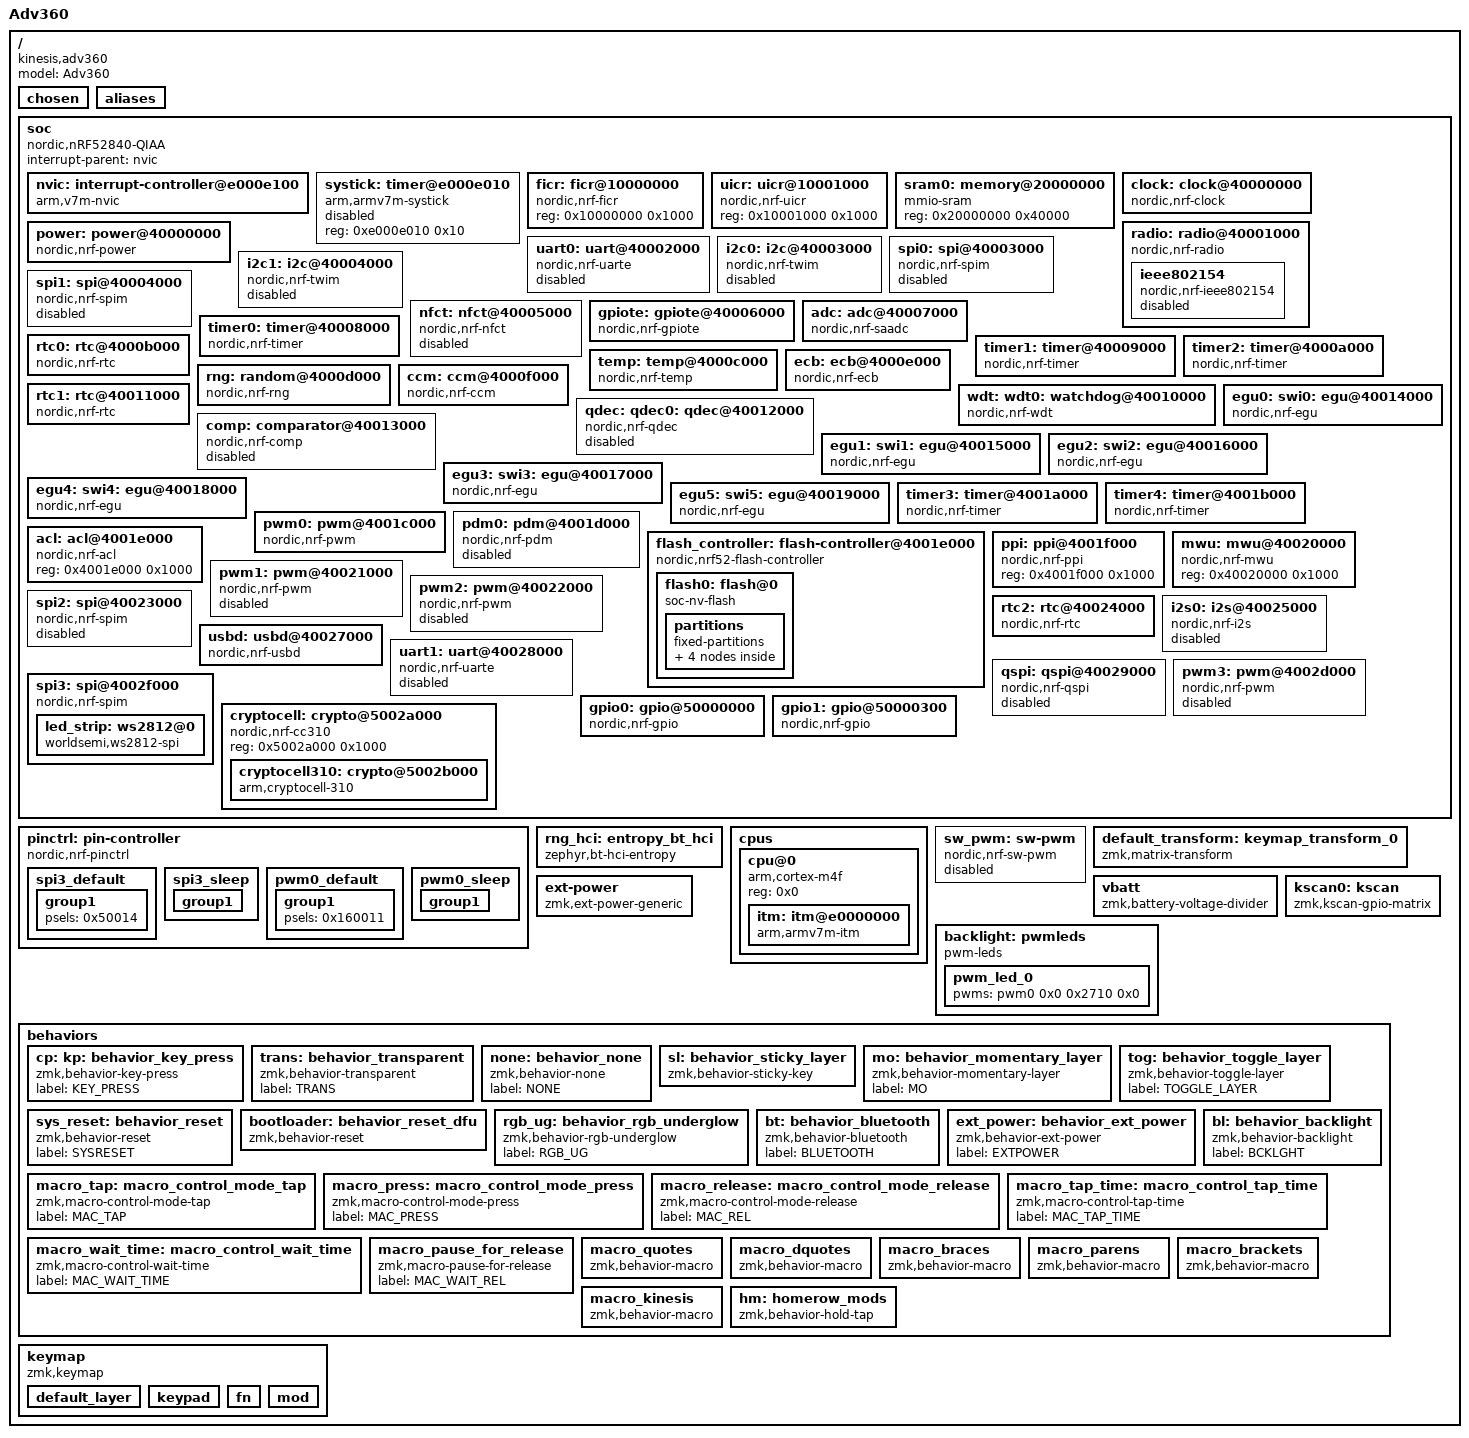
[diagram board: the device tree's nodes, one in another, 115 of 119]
/dts-v1/;

/ {
	#address-cells = < 0x1 >;
	#size-cells = < 0x1 >;
	model = "Adv360";
	compatible = "kinesis,adv360";
	chosen {
		zephyr,entropy = &rng;
		zephyr,flash-controller = &flash_controller;
		zephyr,code-partition = &code_partition;
		zephyr,sram = &sram0;
		zephyr,flash = &flash0;
		zmk,kscan = &kscan0;
		zmk,backlight = &backlight;
		zmk,battery = &vbatt;
		zmk,matrix_transform = &default_transform;
		zmk,underglow = &led_strip;
	};
	aliases {
	};
	soc {
		#address-cells = < 0x1 >;
		#size-cells = < 0x1 >;
		compatible = "nordic,nRF52840-QIAA", "nordic,nRF52840", "nordic,nRF52", "simple-bus";
		interrupt-parent = < &nvic >;
		ranges;
		nvic: interrupt-controller@e000e100 {
			#address-cells = < 0x1 >;
			compatible = "arm,v7m-nvic";
			reg = < 0xe000e100 0xc00 >;
			interrupt-controller;
			#interrupt-cells = < 0x2 >;
			arm,num-irq-priority-bits = < 0x3 >;
			phandle = < 0x1 >;
		};
		systick: timer@e000e010 {
			compatible = "arm,armv7m-systick";
			reg = < 0xe000e010 0x10 >;
			status = "disabled";
		};
		ficr: ficr@10000000 {
			compatible = "nordic,nrf-ficr";
			reg = < 0x10000000 0x1000 >;
			status = "okay";
		};
		uicr: uicr@10001000 {
			compatible = "nordic,nrf-uicr";
			reg = < 0x10001000 0x1000 >;
			status = "okay";
		};
		sram0: memory@20000000 {
			compatible = "mmio-sram";
			reg = < 0x20000000 0x40000 >;
		};
		clock: clock@40000000 {
			compatible = "nordic,nrf-clock";
			reg = < 0x40000000 0x1000 >;
			interrupts = < 0x0 0x1 >;
			status = "okay";
		};
		power: power@40000000 {
			compatible = "nordic,nrf-power";
			reg = < 0x40000000 0x1000 >;
			interrupts = < 0x0 0x1 >;
			status = "okay";
		};
		radio: radio@40001000 {
			compatible = "nordic,nrf-radio";
			reg = < 0x40001000 0x1000 >;
			interrupts = < 0x1 0x1 >;
			status = "okay";
			ieee802154-supported;
			ble-2mbps-supported;
			ble-coded-phy-supported;
			tx-high-power-supported;
			ieee802154: ieee802154 {
				compatible = "nordic,nrf-ieee802154";
				status = "disabled";
			};
		};
		uart0: uart@40002000 {
			compatible = "nordic,nrf-uarte";
			reg = < 0x40002000 0x1000 >;
			interrupts = < 0x2 0x1 >;
			status = "disabled";
		};
		i2c0: i2c@40003000 {
			compatible = "nordic,nrf-twim";
			#address-cells = < 0x1 >;
			#size-cells = < 0x0 >;
			reg = < 0x40003000 0x1000 >;
			clock-frequency = < 0x186a0 >;
			interrupts = < 0x3 0x1 >;
			status = "disabled";
		};
		spi0: spi@40003000 {
			compatible = "nordic,nrf-spim";
			#address-cells = < 0x1 >;
			#size-cells = < 0x0 >;
			reg = < 0x40003000 0x1000 >;
			interrupts = < 0x3 0x1 >;
			max-frequency = < 0x7a1200 >;
			status = "disabled";
		};
		i2c1: i2c@40004000 {
			compatible = "nordic,nrf-twim";
			#address-cells = < 0x1 >;
			#size-cells = < 0x0 >;
			reg = < 0x40004000 0x1000 >;
			clock-frequency = < 0x186a0 >;
			interrupts = < 0x4 0x1 >;
			status = "disabled";
		};
		spi1: spi@40004000 {
			compatible = "nordic,nrf-spim";
			#address-cells = < 0x1 >;
			#size-cells = < 0x0 >;
			reg = < 0x40004000 0x1000 >;
			interrupts = < 0x4 0x1 >;
			max-frequency = < 0x7a1200 >;
			status = "disabled";
		};
		nfct: nfct@40005000 {
			compatible = "nordic,nrf-nfct";
			reg = < 0x40005000 0x1000 >;
			interrupts = < 0x5 0x1 >;
			status = "disabled";
		};
		gpiote: gpiote@40006000 {
			compatible = "nordic,nrf-gpiote";
			reg = < 0x40006000 0x1000 >;
			interrupts = < 0x6 0x5 >;
			status = "okay";
		};
		adc: adc@40007000 {
			compatible = "nordic,nrf-saadc";
			reg = < 0x40007000 0x1000 >;
			interrupts = < 0x7 0x1 >;
			status = "okay";
			#io-channel-cells = < 0x1 >;
			phandle = < 0x8 >;
		};
		timer0: timer@40008000 {
			compatible = "nordic,nrf-timer";
			status = "okay";
			reg = < 0x40008000 0x1000 >;
			cc-num = < 0x4 >;
			interrupts = < 0x8 0x1 >;
			prescaler = < 0x0 >;
		};
		timer1: timer@40009000 {
			compatible = "nordic,nrf-timer";
			status = "okay";
			reg = < 0x40009000 0x1000 >;
			cc-num = < 0x4 >;
			interrupts = < 0x9 0x1 >;
			prescaler = < 0x0 >;
		};
		timer2: timer@4000a000 {
			compatible = "nordic,nrf-timer";
			status = "okay";
			reg = < 0x4000a000 0x1000 >;
			cc-num = < 0x4 >;
			interrupts = < 0xa 0x1 >;
			prescaler = < 0x0 >;
			phandle = < 0x6 >;
		};
		rtc0: rtc@4000b000 {
			compatible = "nordic,nrf-rtc";
			reg = < 0x4000b000 0x1000 >;
			cc-num = < 0x3 >;
			interrupts = < 0xb 0x1 >;
			status = "okay";
			clock-frequency = < 0x8000 >;
			prescaler = < 0x1 >;
		};
		temp: temp@4000c000 {
			compatible = "nordic,nrf-temp";
			reg = < 0x4000c000 0x1000 >;
			interrupts = < 0xc 0x1 >;
			status = "okay";
		};
		rng: random@4000d000 {
			compatible = "nordic,nrf-rng";
			reg = < 0x4000d000 0x1000 >;
			interrupts = < 0xd 0x1 >;
			status = "okay";
		};
		ecb: ecb@4000e000 {
			compatible = "nordic,nrf-ecb";
			reg = < 0x4000e000 0x1000 >;
			interrupts = < 0xe 0x1 >;
			status = "okay";
		};
		ccm: ccm@4000f000 {
			compatible = "nordic,nrf-ccm";
			reg = < 0x4000f000 0x1000 >;
			interrupts = < 0xf 0x1 >;
			length-field-length-8-bits;
			status = "okay";
		};
		wdt: wdt0: watchdog@40010000 {
			compatible = "nordic,nrf-wdt";
			reg = < 0x40010000 0x1000 >;
			interrupts = < 0x10 0x1 >;
			status = "okay";
		};
		rtc1: rtc@40011000 {
			compatible = "nordic,nrf-rtc";
			reg = < 0x40011000 0x1000 >;
			cc-num = < 0x4 >;
			interrupts = < 0x11 0x1 >;
			status = "okay";
			clock-frequency = < 0x8000 >;
			prescaler = < 0x1 >;
		};
		qdec: qdec0: qdec@40012000 {
			compatible = "nordic,nrf-qdec";
			reg = < 0x40012000 0x1000 >;
			interrupts = < 0x12 0x1 >;
			status = "disabled";
		};
		comp: comparator@40013000 {
			compatible = "nordic,nrf-comp";
			reg = < 0x40013000 0x1000 >;
			interrupts = < 0x13 0x1 >;
			status = "disabled";
			#io-channel-cells = < 0x1 >;
		};
		egu0: swi0: egu@40014000 {
			compatible = "nordic,nrf-egu", "nordic,nrf-swi";
			reg = < 0x40014000 0x1000 >;
			interrupts = < 0x14 0x1 >;
			status = "okay";
		};
		egu1: swi1: egu@40015000 {
			compatible = "nordic,nrf-egu", "nordic,nrf-swi";
			reg = < 0x40015000 0x1000 >;
			interrupts = < 0x15 0x1 >;
			status = "okay";
		};
		egu2: swi2: egu@40016000 {
			compatible = "nordic,nrf-egu", "nordic,nrf-swi";
			reg = < 0x40016000 0x1000 >;
			interrupts = < 0x16 0x1 >;
			status = "okay";
		};
		egu3: swi3: egu@40017000 {
			compatible = "nordic,nrf-egu", "nordic,nrf-swi";
			reg = < 0x40017000 0x1000 >;
			interrupts = < 0x17 0x1 >;
			status = "okay";
		};
		egu4: swi4: egu@40018000 {
			compatible = "nordic,nrf-egu", "nordic,nrf-swi";
			reg = < 0x40018000 0x1000 >;
			interrupts = < 0x18 0x1 >;
			status = "okay";
		};
		egu5: swi5: egu@40019000 {
			compatible = "nordic,nrf-egu", "nordic,nrf-swi";
			reg = < 0x40019000 0x1000 >;
			interrupts = < 0x19 0x1 >;
			status = "okay";
		};
		timer3: timer@4001a000 {
			compatible = "nordic,nrf-timer";
			status = "okay";
			reg = < 0x4001a000 0x1000 >;
			cc-num = < 0x6 >;
			interrupts = < 0x1a 0x1 >;
			prescaler = < 0x0 >;
		};
		timer4: timer@4001b000 {
			compatible = "nordic,nrf-timer";
			status = "okay";
			reg = < 0x4001b000 0x1000 >;
			cc-num = < 0x6 >;
			interrupts = < 0x1b 0x1 >;
			prescaler = < 0x0 >;
		};
		pwm0: pwm@4001c000 {
			compatible = "nordic,nrf-pwm";
			reg = < 0x4001c000 0x1000 >;
			interrupts = < 0x1c 0x1 >;
			status = "okay";
			#pwm-cells = < 0x3 >;
			pinctrl-0 = < &pwm0_default >;
			pinctrl-1 = < &pwm0_sleep >;
			pinctrl-names = "default", "sleep";
			phandle = < 0x9 >;
		};
		pdm0: pdm@4001d000 {
			compatible = "nordic,nrf-pdm";
			reg = < 0x4001d000 0x1000 >;
			interrupts = < 0x1d 0x1 >;
			status = "disabled";
		};
		acl: acl@4001e000 {
			compatible = "nordic,nrf-acl";
			reg = < 0x4001e000 0x1000 >;
			status = "okay";
		};
		flash_controller: flash-controller@4001e000 {
			compatible = "nordic,nrf52-flash-controller";
			reg = < 0x4001e000 0x1000 >;
			partial-erase;
			#address-cells = < 0x1 >;
			#size-cells = < 0x1 >;
			flash0: flash@0 {
				compatible = "soc-nv-flash";
				erase-block-size = < 0x1000 >;
				write-block-size = < 0x4 >;
				reg = < 0x0 0x100000 >;
				partitions {
					compatible = "fixed-partitions";
					#address-cells = < 0x1 >;
					#size-cells = < 0x1 >;
					sd_partition: partition@0 {
						label = "softdevice";
						reg = < 0x0 0x26000 >;
					};
					code_partition: partition@26000 {
						label = "code_partition";
						reg = < 0x26000 0xc6000 >;
					};
					storage_partition: partition@ec000 {
						label = "storage";
						reg = < 0xec000 0x8000 >;
					};
					boot_partition: partition@f4000 {
						label = "adafruit_boot";
						reg = < 0xf4000 0xc000 >;
					};
				};
			};
		};
		ppi: ppi@4001f000 {
			compatible = "nordic,nrf-ppi";
			reg = < 0x4001f000 0x1000 >;
			status = "okay";
		};
		mwu: mwu@40020000 {
			compatible = "nordic,nrf-mwu";
			reg = < 0x40020000 0x1000 >;
			status = "okay";
		};
		pwm1: pwm@40021000 {
			compatible = "nordic,nrf-pwm";
			reg = < 0x40021000 0x1000 >;
			interrupts = < 0x21 0x1 >;
			status = "disabled";
			#pwm-cells = < 0x3 >;
		};
		pwm2: pwm@40022000 {
			compatible = "nordic,nrf-pwm";
			reg = < 0x40022000 0x1000 >;
			interrupts = < 0x22 0x1 >;
			status = "disabled";
			#pwm-cells = < 0x3 >;
		};
		spi2: spi@40023000 {
			compatible = "nordic,nrf-spim";
			#address-cells = < 0x1 >;
			#size-cells = < 0x0 >;
			reg = < 0x40023000 0x1000 >;
			interrupts = < 0x23 0x1 >;
			max-frequency = < 0x7a1200 >;
			status = "disabled";
		};
		rtc2: rtc@40024000 {
			compatible = "nordic,nrf-rtc";
			reg = < 0x40024000 0x1000 >;
			cc-num = < 0x4 >;
			interrupts = < 0x24 0x1 >;
			status = "okay";
			clock-frequency = < 0x8000 >;
			prescaler = < 0x1 >;
		};
		i2s0: i2s@40025000 {
			compatible = "nordic,nrf-i2s";
			#address-cells = < 0x1 >;
			#size-cells = < 0x0 >;
			reg = < 0x40025000 0x1000 >;
			interrupts = < 0x25 0x1 >;
			status = "disabled";
		};
		usbd: usbd@40027000 {
			compatible = "nordic,nrf-usbd";
			reg = < 0x40027000 0x1000 >;
			interrupts = < 0x27 0x1 >;
			num-bidir-endpoints = < 0x1 >;
			num-in-endpoints = < 0x7 >;
			num-out-endpoints = < 0x7 >;
			num-isoin-endpoints = < 0x1 >;
			num-isoout-endpoints = < 0x1 >;
			status = "okay";
		};
		uart1: uart@40028000 {
			compatible = "nordic,nrf-uarte";
			reg = < 0x40028000 0x1000 >;
			interrupts = < 0x28 0x1 >;
			status = "disabled";
		};
		qspi: qspi@40029000 {
			compatible = "nordic,nrf-qspi";
			#address-cells = < 0x1 >;
			#size-cells = < 0x0 >;
			reg = < 0x40029000 0x1000 >, < 0x12000000 0x8000000 >;
			reg-names = "qspi", "qspi_mm";
			interrupts = < 0x29 0x1 >;
			status = "disabled";
		};
		pwm3: pwm@4002d000 {
			compatible = "nordic,nrf-pwm";
			reg = < 0x4002d000 0x1000 >;
			interrupts = < 0x2d 0x1 >;
			status = "disabled";
			#pwm-cells = < 0x3 >;
		};
		spi3: spi@4002f000 {
			compatible = "nordic,nrf-spim";
			#address-cells = < 0x1 >;
			#size-cells = < 0x0 >;
			reg = < 0x4002f000 0x1000 >;
			interrupts = < 0x2f 0x1 >;
			max-frequency = < 0x1e84800 >;
			rx-delay-supported;
			rx-delay = < 0x2 >;
			status = "okay";
			pinctrl-0 = < &spi3_default >;
			pinctrl-1 = < &spi3_sleep >;
			pinctrl-names = "default", "sleep";
			led_strip: ws2812@0 {
				compatible = "worldsemi,ws2812-spi";
				label = "WS2812";
				reg = < 0x0 >;
				spi-max-frequency = < 0x3d0900 >;
				chain-length = < 0x3 >;
				spi-one-frame = < 0x70 >;
				spi-zero-frame = < 0x40 >;
				color-mapping = < 0x2 0x1 0x3 >;
			};
		};
		gpio0: gpio@50000000 {
			compatible = "nordic,nrf-gpio";
			gpio-controller;
			reg = < 0x50000000 0x200 0x50000500 0x300 >;
			#gpio-cells = < 0x2 >;
			status = "okay";
			port = < 0x0 >;
			phandle = < 0x7 >;
		};
		gpio1: gpio@50000300 {
			compatible = "nordic,nrf-gpio";
			gpio-controller;
			reg = < 0x50000300 0x200 0x50000800 0x300 >;
			#gpio-cells = < 0x2 >;
			ngpios = < 0x10 >;
			status = "okay";
			port = < 0x1 >;
			phandle = < 0xa >;
		};
		cryptocell: crypto@5002a000 {
			compatible = "nordic,nrf-cc310";
			reg = < 0x5002a000 0x1000 >;
			status = "okay";
			#address-cells = < 0x1 >;
			#size-cells = < 0x1 >;
			cryptocell310: crypto@5002b000 {
				compatible = "arm,cryptocell-310";
				reg = < 0x5002b000 0x1000 >;
				interrupts = < 0x2a 0x1 >;
			};
		};
	};
	pinctrl: pin-controller {
		compatible = "nordic,nrf-pinctrl";
		spi3_default: spi3_default {
			phandle = < 0x4 >;
			group1 {
				psels = < 0x50014 >;
			};
		};
		spi3_sleep: spi3_sleep {
			phandle = < 0x5 >;
			group1 {
				psels = < 0x50014 >;
				low-power-enable;
			};
		};
		pwm0_default: pwm0_default {
			phandle = < 0x2 >;
			group1 {
				psels = < 0x160011 >;
			};
		};
		pwm0_sleep: pwm0_sleep {
			phandle = < 0x3 >;
			group1 {
				psels = < 0x160011 >;
				low-power-enable;
			};
		};
	};
	rng_hci: entropy_bt_hci {
		compatible = "zephyr,bt-hci-entropy";
		status = "okay";
	};
	cpus {
		#address-cells = < 0x1 >;
		#size-cells = < 0x0 >;
		cpu@0 {
			device_type = "cpu";
			compatible = "arm,cortex-m4f";
			reg = < 0x0 >;
			#address-cells = < 0x1 >;
			#size-cells = < 0x1 >;
			itm: itm@e0000000 {
				compatible = "arm,armv7m-itm";
				reg = < 0xe0000000 0x1000 >;
				swo-ref-frequency = < 0x1e84800 >;
			};
		};
	};
	sw_pwm: sw-pwm {
		compatible = "nordic,nrf-sw-pwm";
		status = "disabled";
		generator = < &timer2 >;
		clock-prescaler = < 0x0 >;
		#pwm-cells = < 0x3 >;
	};
	default_transform: keymap_transform_0 {
		compatible = "zmk,matrix-transform";
		columns = < 0x14 >;
		rows = < 0x5 >;
		map = < 0x400 0x401 0x402 0x403 0x404 0x405 0x406 0x40d 0x40e 0x40f 0x410 0x411 0x412 0x413 0x300 0x301 0x302 0x303 0x304 0x305 0x306 0x30d 0x30e 0x30f 0x310 0x311 0x312 0x313 0x200 0x201 0x202 0x203 0x204 0x205 0x206 0x20d 0x20e 0x20f 0x210 0x211 0x212 0x213 0x100 0x101 0x102 0x103 0x104 0x105 0x10e 0x10f 0x110 0x111 0x112 0x113 0x0 0x1 0x2 0x3 0x4 0xf 0x10 0x11 0x12 0x13 0x208 0x209 0x20a 0x20b 0x109 0x10a 0x7 0x8 0x9 0xa 0xb 0xc >;
		col-offset = < 0xa >;
	};
	ext-power {
		compatible = "zmk,ext-power-generic";
		label = "EXT_POWER";
		control-gpios = < &gpio0 0xd 0x0 >;
	};
	vbatt: vbatt {
		compatible = "zmk,battery-voltage-divider";
		io-channels = < &adc 0x2 >;
		output-ohms = < 0x186a0 >;
		full-ohms = < 0x30d40 >;
	};
	backlight: pwmleds {
		compatible = "pwm-leds";
		pwm_led_0 {
			pwms = < &pwm0 0x0 0x2710 0x0 >;
		};
	};
	kscan0: kscan {
		compatible = "zmk,kscan-gpio-matrix";
		diode-direction = "col2row";
		row-gpios = < &gpio0 0x13 0x20 >, < &gpio0 0x5 0x20 >, < &gpio0 0x1f 0x20 >, < &gpio0 0x1e 0x20 >, < &gpio0 0x1d 0x20 >;
		col-gpios = < &gpio0 0xc 0x0 >, < &gpio1 0x9 0x0 >, < &gpio0 0x7 0x0 >, < &gpio1 0xb 0x0 >, < &gpio1 0xa 0x0 >, < &gpio1 0xd 0x0 >, < &gpio1 0xf 0x0 >, < &gpio0 0x3 0x0 >, < &gpio0 0x2 0x0 >, < &gpio0 0x1c 0x0 >;
	};
	behaviors {
		cp: kp: behavior_key_press {
			compatible = "zmk,behavior-key-press";
			label = "KEY_PRESS";
			#binding-cells = < 0x1 >;
			phandle = < 0xb >;
		};
		trans: behavior_transparent {
			compatible = "zmk,behavior-transparent";
			label = "TRANS";
			#binding-cells = < 0x0 >;
			phandle = < 0x10 >;
		};
		none: behavior_none {
			compatible = "zmk,behavior-none";
			label = "NONE";
			#binding-cells = < 0x0 >;
			phandle = < 0xe >;
		};
		sl: behavior_sticky_layer {
			compatible = "zmk,behavior-sticky-key";
			label = "STICKY_LAYER";
			#binding-cells = < 0x1 >;
			release-after-ms = < 0xf423f >;
			bindings = < &mo >;
			quick-release;
			phandle = < 0xf >;
		};
		mo: behavior_momentary_layer {
			compatible = "zmk,behavior-momentary-layer";
			label = "MO";
			#binding-cells = < 0x1 >;
			phandle = < 0xc >;
		};
		tog: behavior_toggle_layer {
			compatible = "zmk,behavior-toggle-layer";
			label = "TOGGLE_LAYER";
			#binding-cells = < 0x1 >;
			phandle = < 0xd >;
		};
		sys_reset: behavior_reset {
			compatible = "zmk,behavior-reset";
			label = "SYSRESET";
			#binding-cells = < 0x0 >;
		};
		bootloader: behavior_reset_dfu {
			compatible = "zmk,behavior-reset";
			label = "BOOTLOAD";
			type = < 0x57 >;
			#binding-cells = < 0x0 >;
			phandle = < 0x12 >;
		};
		rgb_ug: behavior_rgb_underglow {
			compatible = "zmk,behavior-rgb-underglow";
			label = "RGB_UG";
			#binding-cells = < 0x2 >;
			phandle = < 0x13 >;
		};
		bt: behavior_bluetooth {
			compatible = "zmk,behavior-bluetooth";
			label = "BLUETOOTH";
			#binding-cells = < 0x2 >;
			phandle = < 0x11 >;
		};
		ext_power: behavior_ext_power {
			compatible = "zmk,behavior-ext-power";
			label = "EXTPOWER";
			#binding-cells = < 0x1 >;
		};
		bl: behavior_backlight {
			compatible = "zmk,behavior-backlight";
			label = "BCKLGHT";
			#binding-cells = < 0x2 >;
			phandle = < 0x14 >;
		};
		macro_tap: macro_control_mode_tap {
			compatible = "zmk,macro-control-mode-tap";
			label = "MAC_TAP";
			#binding-cells = < 0x0 >;
		};
		macro_press: macro_control_mode_press {
			compatible = "zmk,macro-control-mode-press";
			label = "MAC_PRESS";
			#binding-cells = < 0x0 >;
		};
		macro_release: macro_control_mode_release {
			compatible = "zmk,macro-control-mode-release";
			label = "MAC_REL";
			#binding-cells = < 0x0 >;
		};
		macro_tap_time: macro_control_tap_time {
			compatible = "zmk,macro-control-tap-time";
			label = "MAC_TAP_TIME";
			#binding-cells = < 0x1 >;
		};
		macro_wait_time: macro_control_wait_time {
			compatible = "zmk,macro-control-wait-time";
			label = "MAC_WAIT_TIME";
			#binding-cells = < 0x1 >;
		};
		macro_pause_for_release: macro_pause_for_release {
			compatible = "zmk,macro-pause-for-release";
			label = "MAC_WAIT_REL";
			#binding-cells = < 0x0 >;
		};
		macro_quotes: macro_quotes {
			compatible = "zmk,behavior-macro";
			label = "macro_quotes";
			#binding-cells = < 0x0 >;
			bindings = < &kp 0x70034 >, < &kp 0x70034 >, < &kp 0x70050 >;
		};
		macro_dquotes: macro_dquotes {
			compatible = "zmk,behavior-macro";
			label = "macro_dquotes";
			#binding-cells = < 0x0 >;
			bindings = < &kp 0x2070034 >, < &kp 0x2070034 >, < &kp 0x70050 >;
		};
		macro_braces: macro_braces {
			compatible = "zmk,behavior-macro";
			label = "macro_braces";
			#binding-cells = < 0x0 >;
			bindings = < &kp 0x207002f >, < &kp 0x2070030 >, < &kp 0x70050 >;
		};
		macro_parens: macro_parens {
			compatible = "zmk,behavior-macro";
			label = "macro_parens";
			#binding-cells = < 0x0 >;
			bindings = < &kp 0x2070026 >, < &kp 0x2070027 >, < &kp 0x70050 >;
		};
		macro_brackets: macro_brackets {
			compatible = "zmk,behavior-macro";
			label = "macro_brackets";
			#binding-cells = < 0x0 >;
			bindings = < &kp 0x7002f >, < &kp 0x70030 >, < &kp 0x70050 >;
		};
		macro_kinesis: macro_kinesis {
			compatible = "zmk,behavior-macro";
			label = "macro_kinesis";
			#binding-cells = < 0x0 >;
			bindings = < &kp 0x207000e >, < &kp 0x7000c >, < &kp 0x70011 >, < &kp 0x70008 >, < &kp 0x70016 >, < &kp 0x7000c >, < &kp 0x70016 >;
		};
		hm: homerow_mods {
			compatible = "zmk,behavior-hold-tap";
			label = "HOMEROW_MODS";
			#binding-cells = < 0x2 >;
			tapping-term-ms = < 0xc8 >;
			quick_tap_ms = < 0xaf >;
			flavor = "tap-preferred";
			bindings = < &kp >, < &kp >;
		};
	};
	keymap {
		compatible = "zmk,keymap";
		default_layer {
			bindings = < &kp 0x7002e &kp 0x7001e &kp 0x7001f &kp 0x70020 &kp 0x70021 &kp 0x70022 &tog 0x1 &mo 0x3 &kp 0x70023 &kp 0x70024 &kp 0x70025 &kp 0x70026 &kp 0x70027 &kp 0x7002d &kp 0x7002b &kp 0x70014 &kp 0x7001a &kp 0x70007 &kp 0x70009 &kp 0x7000e &none &none &kp 0x7000d &kp 0x70018 &kp 0x70015 &kp 0x7000f &kp 0x70029 &kp 0x70031 &kp 0x70029 &kp 0x70004 &kp 0x70016 &kp 0x70008 &kp 0x70017 &kp 0x7000a &none &none &kp 0x7001c &kp 0x70011 &kp 0x7000c &kp 0x70012 &kp 0x7000b &kp 0x70034 &kp 0x700e1 &kp 0x7001d &kp 0x7001b &kp 0x70006 &kp 0x70019 &kp 0x70005 &kp 0x70013 &kp 0x70010 &sl 0x1 &kp 0x70037 &kp 0x70038 &kp 0x700e5 &mo 0x2 &kp 0x70035 &kp 0x70039 &kp 0x70050 &kp 0x7004f &kp 0x70052 &kp 0x70051 &kp 0x7002f &kp 0x70030 &mo 0x2 &kp 0x700e0 &kp 0x700e2 &kp 0x700e3 &kp 0x700e4 &kp 0x7004a &kp 0x7004b &kp 0x7002a &kp 0x7004c &kp 0x7004d &kp 0x7004e &kp 0x70028 &kp 0x7002c >;
		};
		keypad {
			bindings = < &kp 0x7002e &kp 0x7001e &kp 0x7001f &kp 0x70020 &kp 0x70021 &kp 0x70022 &trans &mo 0x3 &kp 0x70023 &kp 0x70053 &kp 0x70067 &kp 0x70054 &kp 0x70055 &kp 0x7002d &kp 0x7002b &kp 0x70014 &kp 0x7001a &kp 0x70008 &kp 0x70015 &kp 0x70017 &none &none &kp 0x7001c &kp 0x7005f &kp 0x70060 &kp 0x70061 &kp 0x70056 &kp 0x70031 &kp 0x70029 &kp 0x70004 &kp 0x70016 &kp 0x70007 &kp 0x70009 &kp 0x7000a &none &none &kp 0x7000b &kp 0x7005c &kp 0x7005d &kp 0x7005e &kp 0x70057 &kp 0x70034 &kp 0x700e1 &kp 0x7001d &kp 0x7001b &kp 0x70006 &kp 0x70019 &kp 0x70005 &kp 0x70011 &kp 0x70059 &kp 0x7005a &kp 0x7005b &kp 0x70058 &kp 0x700e5 &mo 0x2 &kp 0x70035 &kp 0x70039 &kp 0x70050 &kp 0x7004f &kp 0x70052 &kp 0x70051 &kp 0x70063 &kp 0x70030 &mo 0x2 &kp 0x700e0 &kp 0x700e2 &kp 0x700e3 &kp 0x700e4 &kp 0x7004a &kp 0x7004b &kp 0x7002a &kp 0x7004c &kp 0x7004d &kp 0x7004e &kp 0x70028 &kp 0x70062 >;
		};
		fn {
			bindings = < &kp 0x7003a &kp 0x7003b &kp 0x7003c &kp 0x7003d &kp 0x7003e &kp 0x7003f &tog 0x1 &mo 0x3 &kp 0x70040 &kp 0x70041 &kp 0x70042 &kp 0x70043 &kp 0x70044 &kp 0x70045 &trans &trans &trans &trans &trans &trans &none &none &trans &trans &trans &trans &trans &trans &trans &trans &trans &trans &trans &trans &none &none &trans &trans &trans &trans &trans &trans &trans &trans &trans &trans &trans &trans &trans &trans &trans &trans &trans &trans &trans &trans &trans &trans &trans &trans &trans &trans &trans &trans &trans &trans &trans &trans &trans &trans &trans &trans &trans &trans &trans &trans >;
		};
		mod {
			bindings = < &none &bt 0x3 0x0 &bt 0x3 0x1 &bt 0x3 0x2 &bt 0x3 0x3 &bt 0x3 0x4 &none &trans &none &none &none &none &none &none &none &none &none &none &none &none &bootloader &bootloader &none &none &none &none &none &none &none &none &none &none &none &none &none &rgb_ug 0xe 0x5 &none &none &none &none &none &none &none &none &none &none &none &none &none &none &none &none &none &none &none &none &none &none &none &bl 0x3 0x0 &bl 0x4 0x0 &none &none &none &none &none &bt 0x0 0x0 &none &none &none &none &none &none &none &bl 0x2 0x0 &rgb_ug 0x0 0x0 >;
		};
	};
};
